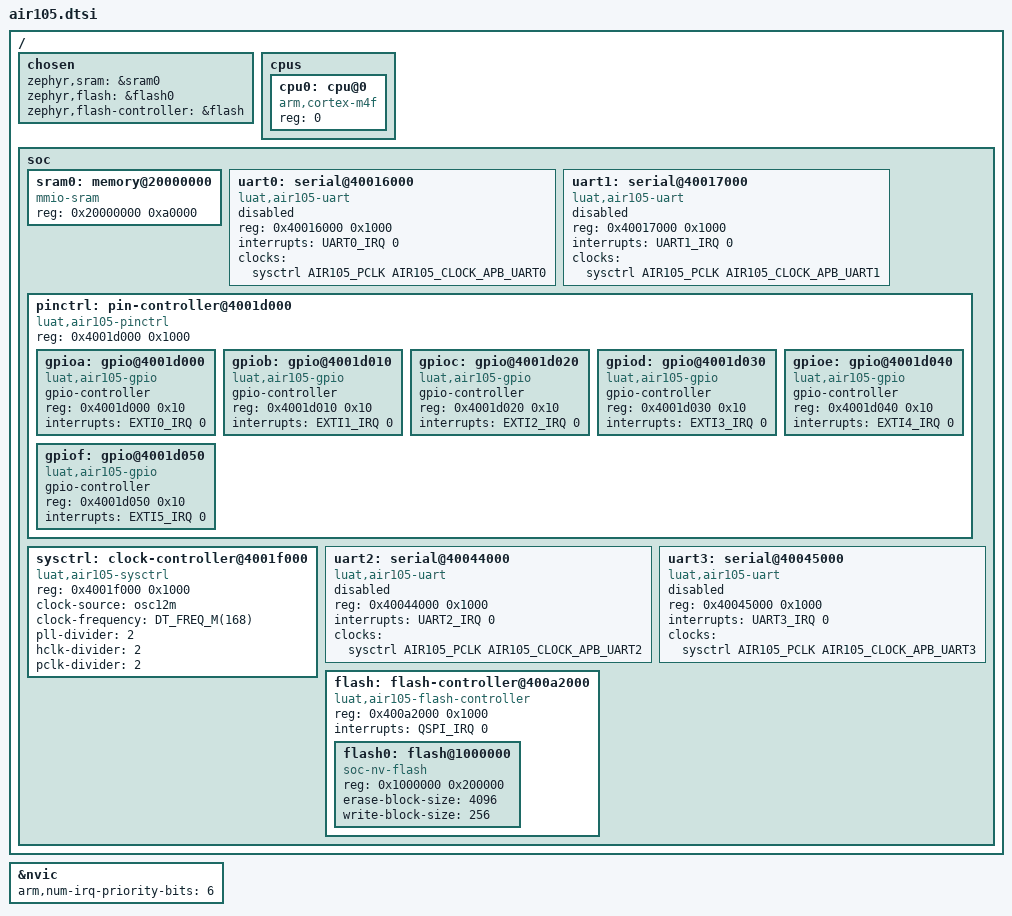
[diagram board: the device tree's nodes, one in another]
/*
 * Copyright (c) 2023 Chen Xingyu <hi@xingrz.me>
 * SPDX-License-Identifier: Apache-2.0
 */

#include <mem.h>
#include <freq.h>

#include <arm/armv7-m.dtsi>
#include <arm/luat/air105-irq.h>

#include <zephyr/dt-bindings/clock/air105-clocks.h>

/ {
	chosen {
		zephyr,sram = &sram0;
		zephyr,flash = &flash0;
		zephyr,flash-controller = &flash;
	};

	cpus {
		#address-cells = <1>;
		#size-cells = <0>;

		cpu0: cpu@0 {
			compatible = "arm,cortex-m4f";
			reg = <0>;
		};
	};

	soc {
		sram0: memory@20000000 {
			compatible = "mmio-sram";
			reg = <0x20000000 0xa0000>;
		};

		uart0: serial@40016000 {
			compatible = "luat,air105-uart";
			reg = <0x40016000 0x1000>;
			interrupts = <UART0_IRQ 0>;
			clocks = <&sysctrl AIR105_PCLK AIR105_CLOCK_APB_UART0>;
			status = "disabled";
		};

		uart1: serial@40017000 {
			compatible = "luat,air105-uart";
			reg = <0x40017000 0x1000>;
			interrupts = <UART1_IRQ 0>;
			clocks = <&sysctrl AIR105_PCLK AIR105_CLOCK_APB_UART1>;
			status = "disabled";
		};

		pinctrl: pin-controller@4001d000 {
			compatible = "luat,air105-pinctrl";
			reg = <0x4001d000 0x1000>;
			#address-cells = <1>;
			#size-cells = <1>;

			gpioa: gpio@4001d000 {
				compatible = "luat,air105-gpio";
				gpio-controller;
				#gpio-cells = <2>;
				reg = <0x4001d000 0x10>;
				interrupts = <EXTI0_IRQ 0>;
			};

			gpiob: gpio@4001d010 {
				compatible = "luat,air105-gpio";
				gpio-controller;
				#gpio-cells = <2>;
				reg = <0x4001d010 0x10>;
				interrupts = <EXTI1_IRQ 0>;
			};

			gpioc: gpio@4001d020 {
				compatible = "luat,air105-gpio";
				gpio-controller;
				#gpio-cells = <2>;
				reg = <0x4001d020 0x10>;
				interrupts = <EXTI2_IRQ 0>;
			};

			gpiod: gpio@4001d030 {
				compatible = "luat,air105-gpio";
				gpio-controller;
				#gpio-cells = <2>;
				reg = <0x4001d030 0x10>;
				interrupts = <EXTI3_IRQ 0>;
			};

			gpioe: gpio@4001d040 {
				compatible = "luat,air105-gpio";
				gpio-controller;
				#gpio-cells = <2>;
				reg = <0x4001d040 0x10>;
				interrupts = <EXTI4_IRQ 0>;
			};

			gpiof: gpio@4001d050 {
				compatible = "luat,air105-gpio";
				gpio-controller;
				#gpio-cells = <2>;
				reg = <0x4001d050 0x10>;
				interrupts = <EXTI5_IRQ 0>;
			};
		};

		sysctrl: clock-controller@4001f000 {
			compatible = "luat,air105-sysctrl";
			reg = <0x4001f000 0x1000>;
			clock-source = "osc12m";
			clock-frequency = <DT_FREQ_M(168)>;
			pll-divider = <2>;
			hclk-divider = <2>;
			pclk-divider = <2>;
			#clock-cells = <2>;
		};

		uart2: serial@40044000 {
			compatible = "luat,air105-uart";
			reg = <0x40044000 0x1000>;
			interrupts = <UART2_IRQ 0>;
			clocks = <&sysctrl AIR105_PCLK AIR105_CLOCK_APB_UART2>;
			status = "disabled";
		};

		uart3: serial@40045000 {
			compatible = "luat,air105-uart";
			reg = <0x40045000 0x1000>;
			interrupts = <UART3_IRQ 0>;
			clocks = <&sysctrl AIR105_PCLK AIR105_CLOCK_APB_UART3>;
			status = "disabled";
		};

		flash: flash-controller@400a2000 {
			compatible = "luat,air105-flash-controller";
			reg = <0x400a2000 0x1000>;
			interrupts = <QSPI_IRQ 0>;
			#address-cells = <1>;
			#size-cells = <1>;

			flash0: flash@1000000 {
				compatible = "soc-nv-flash";
				reg = <0x1000000 0x200000>;
				erase-block-size = <4096>;
				write-block-size = <256>;
			};
		};
	};
};

&nvic {
	arm,num-irq-priority-bits = <6>;
};
